# ADuCM302x register map
Vendor: Analog Devices; Series: ADuCM302x; File version: 1p0
CPU: CM3 r0p1, little endian, no MPU, no FPU, 3 interrupt priority bits
Registers are 32-bit, read-write, reset 0x0 unless marked. A register's access mark holds for its fields unless they carry their own. Offsets are from the block's base; [hi:lo] are bit positions; {n}, {i} and the like mark numbered series.

## CLKG0_OSC — Clocking
Base 0x4004C100
0x0C KEY — Key Protection for CLKG_OSC_CTL
  [15:0] VALUE wo range 0x00000000..0x0000FFFF — Oscillator K
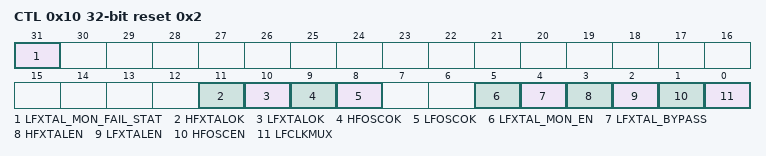
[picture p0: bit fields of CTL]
0x10 CTL reset 0x2 — Oscillator Control
  [31] LFXTAL_MON_FAIL_STAT — LFXTAL Not Stable
    0=LFXTAL_RUNNING (LFXTAL is running fine); 1=LFXTAL_NOTRUNNING (LFXTAL is not running)
  [11] HFXTALOK ro — Status of HFXTAL Oscillator
  [10] LFXTALOK ro — Status of LFXTAL Oscillator
  [9] HFOSCOK ro — Status of HFOSC
  [8] LFOSCOK ro — Status of LFOSC Oscillator
  [5] LFXTAL_MON_EN — LFXTAL Clock Monitor and Clock Fail Interrupt Enable
  [4] LFXTAL_BYPASS — Low Frequency Crystal Oscillator Bypass
  [3] HFXTALEN — High Frequency Crystal Oscillator Enable
  [2] LFXTALEN — Low Frequency Crystal Oscillator Enable
  [1] HFOSCEN — High Frequency Internal Oscillator Enable
  [0] LFCLKMUX — 32kHz Clock Select Mux

## PMG0_TST — Power Management
Base 0x4004C200
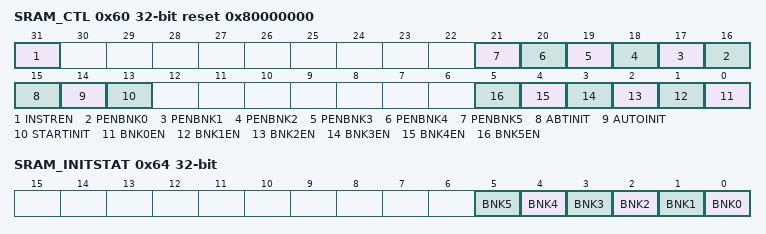
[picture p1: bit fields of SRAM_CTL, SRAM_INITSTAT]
0x60 SRAM_CTL reset 0x80000000 — Control for SRAM Parity and Instruction SRAM
  [31] INSTREN range 0x00000000..0x00000001 — Enables Instruction SRAM
  [n+16] PENBNK{n} range 0x00000000..0x00000001 (n=0..5) — Enable Parity Check SRAM Bank {n}
  [15] ABTINIT range 0x00000000..0x00000001 — Abort Current Initialization. Self-cleared
  [14] AUTOINIT range 0x00000000..0x00000001 — Automatic Initialization on Wakeup from Hibernate Mode
  [13] STARTINIT range 0x00000000..0x00000001 — Write 1 to Trigger Initialization
  [n] BNK{n}EN range 0x00000000..0x00000001 (n=0..5) — Enable Initialization of SRAM Bank {n}
0x64 SRAM_INITSTAT — Initialization Status Register
  [n] BNK{n} ro (n=0..5) — Initialization Done of SRAM Bank {n}
0x68 CLR_LATCH_GPIOS 16-bit — Clear GPIO After Shutdown Mode
  [15:0] VALUE wo range 0x00000000..0x0000FFFF — Clear GPIOs Latches
0x6C SCRPAD_IMG — Scratch Pad Image
  [31:0] DATA range 0x00000000..0xFFFFFFFF — Scratch Image
0x70 SCRPAD_3V_RD — Scratch Pad Saved in Battery Domain
  [31:0] DATA ro — Reading the Scratch Pad Stored in Shutdown Mode

## CLKG0_CLK — Clocking
Base 0x4004C300
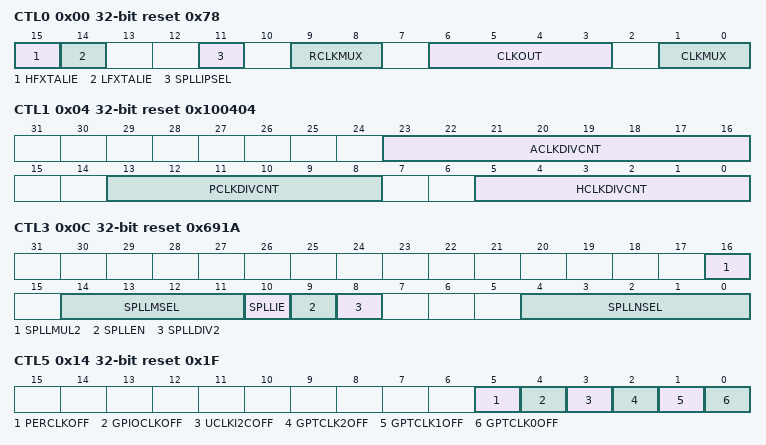
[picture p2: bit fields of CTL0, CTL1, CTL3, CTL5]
0x00 CTL0 reset 0x78 — Miscellaneous Clock Settings
  [15] HFXTALIE — High Frequency Crystal Interrupt Enable
  [14] LFXTALIE — Low Frequency Crystal Interrupt Enable
  [11] SPLLIPSEL — SPLL Source Select Mux
  [9:8] RCLKMUX — Flash Reference Clock and HP Buck Source Mux
  [6:3] CLKOUT — GPIO Clock Out Select (for Debug)
  [1:0] CLKMUX — Clock Mux Select
0x04 CTL1 reset 0x100404 — Clock Dividers
  [23:16] ACLKDIVCNT range 0x00000000..0x000000FF — ACLK Divide Count
  [13:8] PCLKDIVCNT range 0x00000000..0x0000003F — PCLK Divide Count
  [5:0] HCLKDIVCNT range 0x00000000..0x0000003F — HCLK Divide Count
0x0C CTL3 reset 0x691A — System PLL
  [16] SPLLMUL2 — System PLL Multiply by 2
  [14:11] SPLLMSEL range 0x00000000..0x0000000F — System PLL M Divider
  [10] SPLLIE — System PLL Interrupt Enable
  [9] SPLLEN — System PLL Enable
  [8] SPLLDIV2 — System PLL Division by 2
  [4:0] SPLLNSEL range 0x00000000..0x0000001F — System PLL N Multiplier
0x14 CTL5 reset 0x1F — User Clock Gating Control
  [5] PERCLKOFF — Disables All Clocks Connected to All Peripherals
    0=PERIPH_CLK_ACT (Clocks to all peripherals are active); 1=PERIPH_CLK_OFF (Clocks to all peripherals are gated off)
  [4] GPIOCLKOFF — GPIO Clock Control
  [3] UCLKI2COFF — I2C Clock User Control
  [2] GPTCLK2OFF — Timer 2 User Control
  [1] GPTCLK1OFF — Timer 1 User Control
  [0] GPTCLK0OFF — Timer 0 User Control
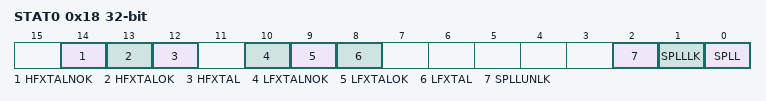
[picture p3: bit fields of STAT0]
0x18 STAT0 — Clocking Status
  [14] HFXTALNOK — HF Crystal Not Stable
  [13] HFXTALOK — HF Crystal Stable
  [12] HFXTAL ro — HF Crystal Status
  [10] LFXTALNOK — LF Crystal Not Stable
  [9] LFXTALOK — LF Crystal Stable
  [8] LFXTAL ro — LF Crystal Status
  [2] SPLLUNLK — System PLL Unlock
  [1] SPLLLK — System PLL Lock
  [0] SPLL ro — System PLL Status

## BUSM0 — Bus matrix
Base 0x4004C800
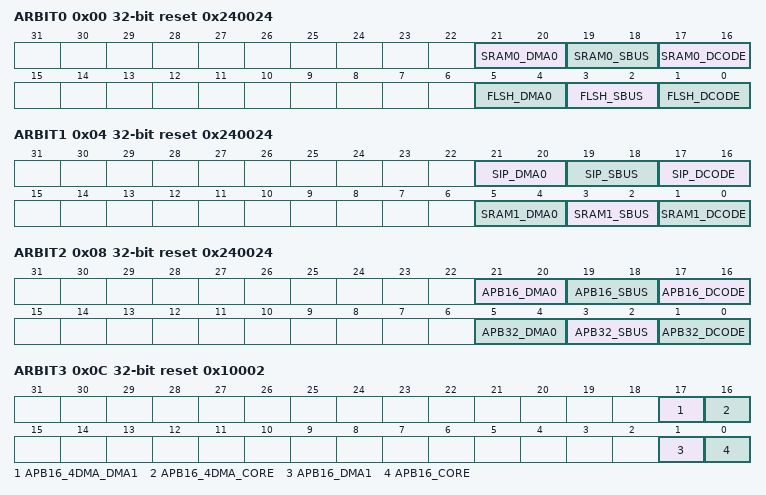
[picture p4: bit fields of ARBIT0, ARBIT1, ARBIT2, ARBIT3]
0x00 ARBIT0 reset 0x240024 — Arbitration Priority Configuration for FLASH and SRAM0
  [21:20] SRAM0_DMA0 range 0x00000000..0x00000003 — SRAM0 priority for DMA0
  [19:18] SRAM0_SBUS range 0x00000000..0x00000003 — SRAM0 priority for SBUS
  [17:16] SRAM0_DCODE range 0x00000000..0x00000003 — SRAM0 priority for Dcode
  [5:4] FLSH_DMA0 range 0x00000000..0x00000003 — Flash priority for DMA0
  [3:2] FLSH_SBUS range 0x00000000..0x00000003 — Flash priority for SBUS
  [1:0] FLSH_DCODE range 0x00000000..0x00000003 — Flash priority for DCODE
0x04 ARBIT1 reset 0x240024 — Arbitration Priority Configuration for SRAM1 and SIP
  [21:20] SIP_DMA0 range 0x00000000..0x00000003 — SIP priority for DMA0
  [19:18] SIP_SBUS range 0x00000000..0x00000003 — SIP priority for SBUS
  [17:16] SIP_DCODE range 0x00000000..0x00000003 — SIP priority for DCODE
  [5:4] SRAM1_DMA0 range 0x00000000..0x00000003 — SRAM1 priority for DMA0
  [3:2] SRAM1_SBUS range 0x00000000..0x00000003 — SRAM1 priority for SBUS
  [1:0] SRAM1_DCODE range 0x00000000..0x00000003 — SRAM1 priority for Dcode
0x08 ARBIT2 reset 0x240024 — Arbitration Priority Configuration for APB32 and APB16
  [21:20] APB16_DMA0 range 0x00000000..0x00000003 — APB16 priority for DMA0
  [19:18] APB16_SBUS range 0x00000000..0x00000003 — APB16 priority for SBUS
  [17:16] APB16_DCODE range 0x00000000..0x00000003 — APB16 priority for DCODE
  [5:4] APB32_DMA0 range 0x00000000..0x00000003 — APB32 priority for DMA0
  [3:2] APB32_SBUS range 0x00000000..0x00000003 — APB32 priority for SBUS
  [1:0] APB32_DCODE range 0x00000000..0x00000003 — APB32 priority for DCODE
0x0C ARBIT3 reset 0x10002 — Arbitration Priority Configuration for APB16 priority for core and for DMA1
  [17] APB16_4DMA_DMA1 range 0x00000000..0x00000001 — APB16 for dma priority for DMA1
  [16] APB16_4DMA_CORE range 0x00000000..0x00000001 — APB16 for dma priority for CORE
  [1] APB16_DMA1 range 0x00000000..0x00000001 — APB16 priority for DMA1
  [0] APB16_CORE range 0x00000000..0x00000001 — APB16 priority for CORE
